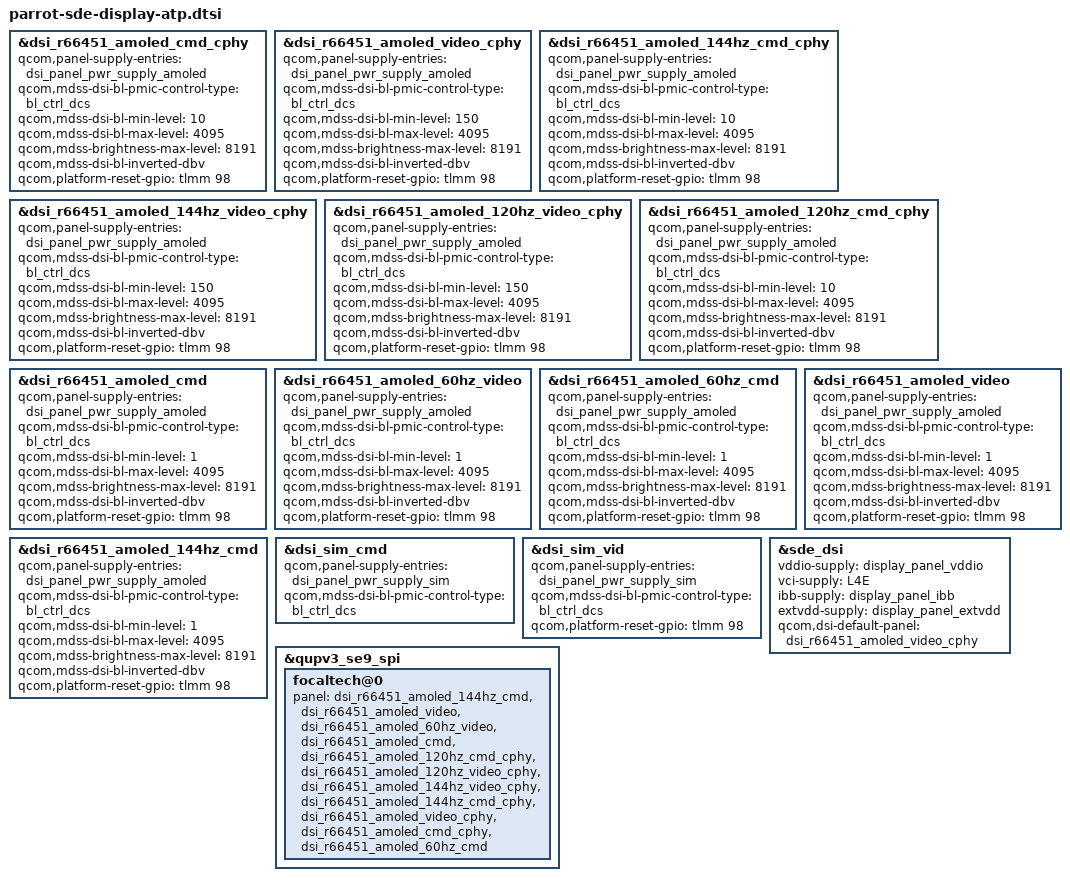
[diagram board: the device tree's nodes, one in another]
#include "parrot-sde-display.dtsi"

&dsi_r66451_amoled_cmd_cphy {
	qcom,panel-supply-entries = <&dsi_panel_pwr_supply_amoled>;
	qcom,mdss-dsi-bl-pmic-control-type = "bl_ctrl_dcs";
	qcom,mdss-dsi-bl-min-level = <10>;
	qcom,mdss-dsi-bl-max-level = <4095>;
	qcom,mdss-brightness-max-level = <8191>;
	qcom,mdss-dsi-bl-inverted-dbv;
	qcom,platform-reset-gpio = <&tlmm 98 0>;
};

&dsi_r66451_amoled_video_cphy {
	qcom,panel-supply-entries = <&dsi_panel_pwr_supply_amoled>;
	qcom,mdss-dsi-bl-pmic-control-type = "bl_ctrl_dcs";
	qcom,mdss-dsi-bl-min-level = <150>;
	qcom,mdss-dsi-bl-max-level = <4095>;
	qcom,mdss-brightness-max-level = <8191>;
	qcom,mdss-dsi-bl-inverted-dbv;
	qcom,platform-reset-gpio = <&tlmm 98 0>;
};

&dsi_r66451_amoled_144hz_cmd_cphy {
	qcom,panel-supply-entries = <&dsi_panel_pwr_supply_amoled>;
	qcom,mdss-dsi-bl-pmic-control-type = "bl_ctrl_dcs";
	qcom,mdss-dsi-bl-min-level = <10>;
	qcom,mdss-dsi-bl-max-level = <4095>;
	qcom,mdss-brightness-max-level = <8191>;
	qcom,mdss-dsi-bl-inverted-dbv;
	qcom,platform-reset-gpio = <&tlmm 98 0>;
};

&dsi_r66451_amoled_144hz_video_cphy {
	qcom,panel-supply-entries = <&dsi_panel_pwr_supply_amoled>;
	qcom,mdss-dsi-bl-pmic-control-type = "bl_ctrl_dcs";
	qcom,mdss-dsi-bl-min-level = <150>;
	qcom,mdss-dsi-bl-max-level = <4095>;
	qcom,mdss-brightness-max-level = <8191>;
	qcom,mdss-dsi-bl-inverted-dbv;
	qcom,platform-reset-gpio = <&tlmm 98 0>;
};

&dsi_r66451_amoled_120hz_video_cphy {
	qcom,panel-supply-entries = <&dsi_panel_pwr_supply_amoled>;
	qcom,mdss-dsi-bl-pmic-control-type = "bl_ctrl_dcs";
	qcom,mdss-dsi-bl-min-level = <150>;
	qcom,mdss-dsi-bl-max-level = <4095>;
	qcom,mdss-brightness-max-level = <8191>;
	qcom,mdss-dsi-bl-inverted-dbv;
	qcom,platform-reset-gpio = <&tlmm 98 0>;
};

&dsi_r66451_amoled_120hz_cmd_cphy {
	qcom,panel-supply-entries = <&dsi_panel_pwr_supply_amoled>;
	qcom,mdss-dsi-bl-pmic-control-type = "bl_ctrl_dcs";
	qcom,mdss-dsi-bl-min-level = <10>;
	qcom,mdss-dsi-bl-max-level = <4095>;
	qcom,mdss-brightness-max-level = <8191>;
	qcom,mdss-dsi-bl-inverted-dbv;
	qcom,platform-reset-gpio = <&tlmm 98 0>;
};

&dsi_r66451_amoled_cmd {
	qcom,panel-supply-entries = <&dsi_panel_pwr_supply_amoled>;
	qcom,mdss-dsi-bl-pmic-control-type = "bl_ctrl_dcs";
	qcom,mdss-dsi-bl-min-level = <1>;
	qcom,mdss-dsi-bl-max-level = <4095>;
	qcom,mdss-brightness-max-level = <8191>;
	qcom,mdss-dsi-bl-inverted-dbv;
	qcom,platform-reset-gpio = <&tlmm 98 0>;
};

&dsi_r66451_amoled_60hz_video {
	qcom,panel-supply-entries = <&dsi_panel_pwr_supply_amoled>;
	qcom,mdss-dsi-bl-pmic-control-type = "bl_ctrl_dcs";
	qcom,mdss-dsi-bl-min-level = <1>;
	qcom,mdss-dsi-bl-max-level = <4095>;
	qcom,mdss-brightness-max-level = <8191>;
	qcom,mdss-dsi-bl-inverted-dbv;
	qcom,platform-reset-gpio = <&tlmm 98 0>;
};

&dsi_r66451_amoled_60hz_cmd {
	qcom,panel-supply-entries = <&dsi_panel_pwr_supply_amoled>;
	qcom,mdss-dsi-bl-pmic-control-type = "bl_ctrl_dcs";
	qcom,mdss-dsi-bl-min-level = <1>;
	qcom,mdss-dsi-bl-max-level = <4095>;
	qcom,mdss-brightness-max-level = <8191>;
	qcom,mdss-dsi-bl-inverted-dbv;
	qcom,platform-reset-gpio = <&tlmm 98 0>;
};

&dsi_r66451_amoled_video {
	qcom,panel-supply-entries = <&dsi_panel_pwr_supply_amoled>;
	qcom,mdss-dsi-bl-pmic-control-type = "bl_ctrl_dcs";
	qcom,mdss-dsi-bl-min-level = <1>;
	qcom,mdss-dsi-bl-max-level = <4095>;
	qcom,mdss-brightness-max-level = <8191>;
	qcom,mdss-dsi-bl-inverted-dbv;
	qcom,platform-reset-gpio = <&tlmm 98 0>;
};

&dsi_r66451_amoled_144hz_cmd {
	qcom,panel-supply-entries = <&dsi_panel_pwr_supply_amoled>;
	qcom,mdss-dsi-bl-pmic-control-type = "bl_ctrl_dcs";
	qcom,mdss-dsi-bl-min-level = <1>;
	qcom,mdss-dsi-bl-max-level = <4095>;
	qcom,mdss-brightness-max-level = <8191>;
	qcom,mdss-dsi-bl-inverted-dbv;
	qcom,platform-reset-gpio = <&tlmm 98 0>;
};

&dsi_sim_cmd {
	qcom,panel-supply-entries = <&dsi_panel_pwr_supply_sim>;
	qcom,mdss-dsi-bl-pmic-control-type = "bl_ctrl_dcs";
};

&dsi_sim_vid {
	qcom,panel-supply-entries = <&dsi_panel_pwr_supply_sim>;
	qcom,mdss-dsi-bl-pmic-control-type = "bl_ctrl_dcs";
	qcom,platform-reset-gpio = <&tlmm 98 0>;
};

&sde_dsi {
	vddio-supply = <&display_panel_vddio>;
	vci-supply = <&L4E>;
	ibb-supply = <&display_panel_ibb>;
	extvdd-supply = <&display_panel_extvdd>;

	qcom,dsi-default-panel = <&dsi_r66451_amoled_video_cphy>;
};

&qupv3_se9_spi {
	focaltech@0 {
		panel = <&dsi_r66451_amoled_144hz_cmd
			&dsi_r66451_amoled_video
			&dsi_r66451_amoled_60hz_video
			&dsi_r66451_amoled_cmd
			&dsi_r66451_amoled_120hz_cmd_cphy
			&dsi_r66451_amoled_120hz_video_cphy
			&dsi_r66451_amoled_144hz_video_cphy
			&dsi_r66451_amoled_144hz_cmd_cphy
			&dsi_r66451_amoled_video_cphy
			&dsi_r66451_amoled_cmd_cphy
			&dsi_r66451_amoled_60hz_cmd>;
	};
};
